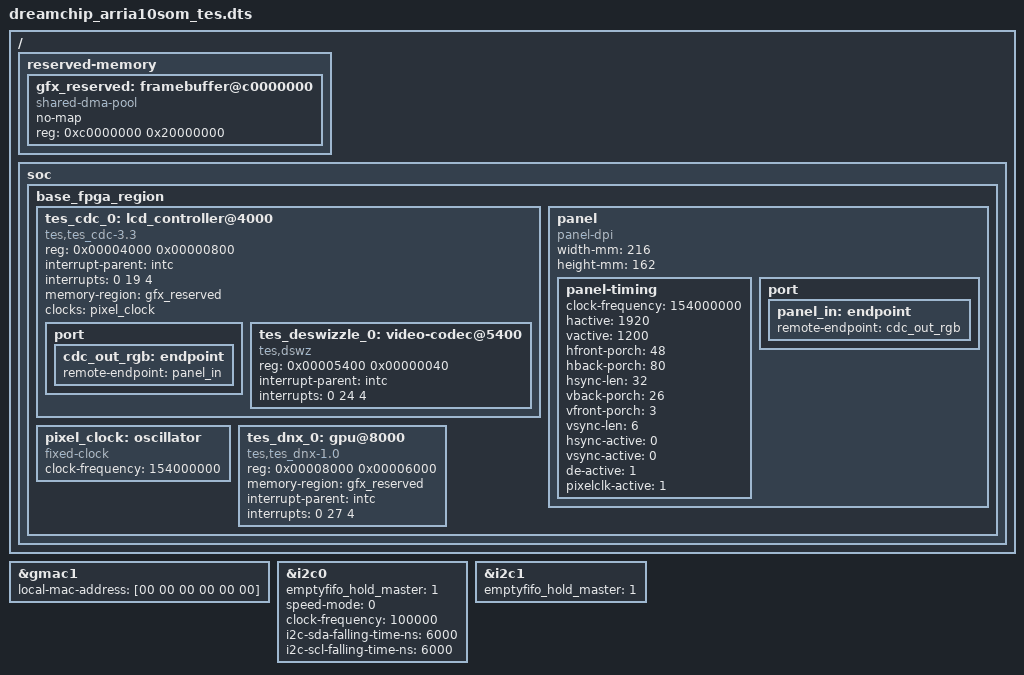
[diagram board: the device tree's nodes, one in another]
/*
 * Copyright (C) 2017 TES Electronic Solutions GmbH. All rights reserved.
 *
 * This program is free software; you can redistribute it and/or modify
 * it under the terms and conditions of the GNU General Public License,
 * version 2, as published by the Free Software Foundation.
 *
 * This program is distributed in the hope it will be useful, but WITHOUT
 * ANY WARRANTY; without even the implied warranty of MERCHANTABILITY or
 * FITNESS FOR A PARTICULAR PURPOSE.  See the GNU General Public License for
 * more details.
 *
 * You should have received a copy of the GNU General Public License along with
 * this program.  If not, see <http://www.gnu.org/licenses/>.
 */

/dts-v1/;
#include "dreamchip_arria10som.dtsi"

&gmac1 {
  local-mac-address = "[00 00 00 00 00 00]"; // dummy address to support fdt boardsetup command
};

&i2c0 {
        status = "okay";        /* embeddedsw.dts.params.status type STRING */
	emptyfifo_hold_master = <1>;	/* embeddedsw.dts.params.emptyfifo_hold_master type NUMBER */
        speed-mode = <0>;       /* appended from boardinfo */
        clock-frequency = <100000>;     /* appended from boardinfo */
        i2c-sda-falling-time-ns = <6000>;       /* appended from boardinfo */
        i2c-scl-falling-time-ns = <6000>;       /* appended from boardinfo */
};

&i2c1 {
        status = "okay";
	emptyfifo_hold_master = <1>;	/* embeddedsw.dts.params.emptyfifo_hold_master type NUMBER */
};


/{
        reserved-memory {
                #address-cells = <1>;
                #size-cells = <1>;
                ranges;

                gfx_reserved: framebuffer@c0000000 {
			compatible = "shared-dma-pool";
			no-map;
		        reg = <0xc0000000 0x20000000>;
		};
        };

	soc{
		base_fpga_region {
		
			ranges = < 0x00004000 0xff204000 0x0800
			           0x00005400 0xff205400 0x0040
				   0x00008000 0xff208000 0x6000 >;
		
			tes_cdc_0: lcd_controller@4000 {
				compatible = "tes,tes_cdc-3.3", "tes,cdc-3.3";
                		#address-cells = <1>;
                		#size-cells = <1>;
				ranges;

				reg = <0x00004000 0x00000800>;
				interrupt-parent = <&intc>;
				interrupts = <0 19 4>;
				
				memory-region = <&gfx_reserved>;

				clocks = <&pixel_clock>;
				
				port {
					cdc_out_rgb: endpoint {
						remote-endpoint = <&panel_in>;
					};
				};

				tes_deswizzle_0: video-codec@5400 {
					compatible = "tes,dswz";
					reg = <0x00005400 0x00000040>;
					interrupt-parent = <&intc>;
					interrupts = <0 24 4>;
				};
			}; //end lcd_controller@0x00004000 (tes_cdc_0)

			panel {
				compatible = "panel-dpi";
		
				width-mm = <216>;
				height-mm = <162>;
				
				panel-timing {
					clock-frequency = <154000000>;
					hactive = <1920>;
					vactive = <1200>;
					hfront-porch = <48>;
					hback-porch = <80>;
					hsync-len = <32>;
					vback-porch = <26>;
					vfront-porch = <3>;
					vsync-len = <6>;
				
					hsync-active = <0>;
					vsync-active = <0>;
					de-active = <1>;
					pixelclk-active = <1>;
				};	
				port {
					panel_in: endpoint {
						remote-endpoint = <&cdc_out_rgb>;
					};
		                };
			};

		
			pixel_clock: oscillator {
				compatible = "fixed-clock";
				#clock-cells = <0>;
				clock-frequency = <154000000>;
			};
		
			tes_dnx_0: gpu@8000 {
				compatible = "tes,tes_dnx-1.0", "tes,dnx-1.0";
				reg = <0x00008000 0x00006000>;
				
				memory-region = <&gfx_reserved>;

				interrupt-parent = <&intc>;
				interrupts = <0 27 4>;
			};
		};
	};
};
